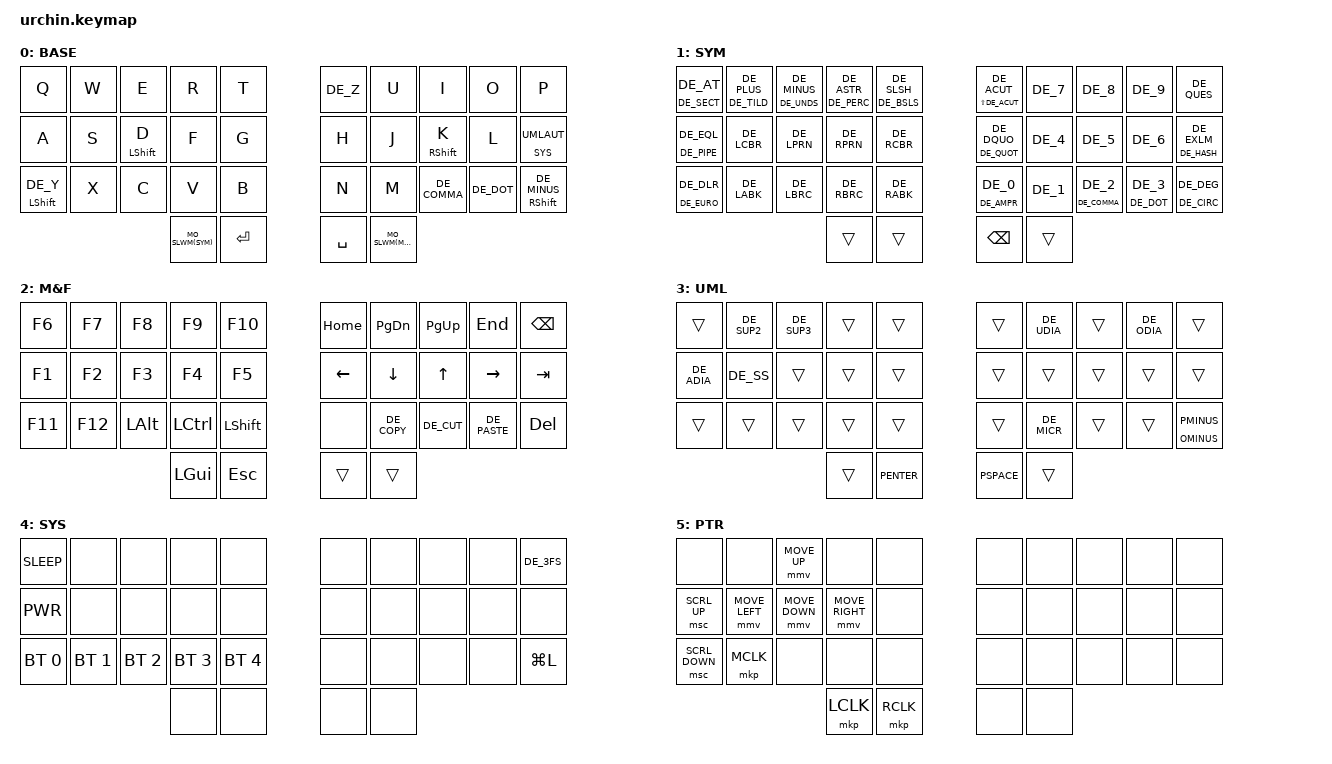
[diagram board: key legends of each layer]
/*
 * Copyright (c) 2020 The ZMK Contributors
 *
 * SPDX-License-Identifier: MIT
 */

#include <behaviors.dtsi>
#include <dt-bindings/zmk/outputs.h>
#include <dt-bindings/zmk/bt.h>
#include <dt-bindings/zmk/keys.h>

#define ZMK_POINTING_DEFAULT_MOVE_VAL 600  // default: 600
#define ZMK_POINTING_DEFAULT_SCRL_VAL 10   // default: 10
#include <dt-bindings/zmk/pointing.h>

#include "keys_de.h"

#define MO_SLWM(layer) &mo_slwm layer layer     // Momentary and sticky layer

#define DEFAULT 0
#define SYM     1
#define MOVEFKT 2
#define UMLAUT  3
#define SYS     4
#define POINTER 5

/*
 * Combos for ESC, Backspace, TAB and ENTER
 */

/ {
    combos {
        compatible = "zmk,combos";
        combo_esc {
            timeout-ms = <50>;
            key-positions = <1 2>;
            layers = <DEFAULT SYM MOVEFKT UMLAUT>;
            bindings = <&kp ESC>;
            slow-release;
        };
        combo_bksp {
            timeout-ms = <75>;
            key-positions = <7 8>;
            layers = <DEFAULT SYM MOVEFKT UMLAUT>;
            bindings = <&kp BSPC>;
            slow-release;
        };
        combo_tab {
            timeout-ms = <50>;
            key-positions = <21 22>;
            layers = <DEFAULT SYM MOVEFKT UMLAUT>;
            bindings = <&kp TAB>;
            slow-release;
        };
        combo_enter {
            timeout-ms = <50>;
            key-positions = <27 28>;
            layers = <DEFAULT SYM MOVEFKT  UMLAUT>;
            bindings = <&kp ENTER>;
            slow-release;
        };
        combo_btclr {
            timeout-ms = <50>;
            key-positions = <0 10 20>;
            layers = <SYS>;
            bindings = <&bt BT_CLR>;
        };
        combo_prefout {
            timeout-ms = <50>;
            key-positions = <4 5>;
            layers = <SYS>;
            bindings = <&out OUT_TOG>;
        };
        combo_cword {
            timeout-ms = <50>;
            key-positions = <13 16>;
            layers = <DEFAULT>;
            bindings = <&caps_word>;
        };
        combo_lctl {
            timeout-ms = <50>;
            key-positions = <12 13>;
            layers = <DEFAULT SYM MOVEFKT UMLAUT>;
            bindings = <&kp LCTL>;
            slow-release;
        };
        combo_lalt {
            timeout-ms = <50>;
            key-positions = <11 13>;
            layers = <DEFAULT SYM MOVEFKT UMLAUT>;
            bindings = <&kp LALT>;
            slow-release;
        };
        combo_lgui {
            timeout-ms = <50>;
            key-positions = <10 13>;
            layers = <DEFAULT SYM MOVEFKT UMLAUT>;
            bindings = <&kp LGUI>;
            slow-release;
        };
        combo_rctl {
            timeout-ms = <50>;
            key-positions = <16 17>;
            layers = <DEFAULT SYM MOVEFKT UMLAUT>;
            bindings = <&kp RCTL>;
            slow-release;
        };
        combo_ralt {
            timeout-ms = <50>;
            key-positions = <16 18>;
            layers = <DEFAULT SYM MOVEFKT UMLAUT>;
            bindings = <&kp LALT>;
            slow-release;
        };
        combo_rapp {
            timeout-ms = <50>;
            key-positions = <16 19>;
            layers = <DEFAULT SYM MOVEFKT UMLAUT>;
            bindings = <&kp K_APP>;
            slow-release;
        };
        combo_pointer {
            timeout-ms = <50>;
            key-positions = <17 33>;
            layers = <DEFAULT SYM MOVEFKT UMLAUT>;
            bindings = <&mo POINTER>;
            slow-release;
        };
    };
};

/ {
    macros {
        apwd: apwd {
            compatible = "zmk,behavior-macro";
            #binding-cells = <0>;
            bindings
                = <&macro_press &kp LSHFT>
                , <&macro_tap &kp S>
                , <&macro_release &kp LSHFT>
                , <&macro_tap &kp O &kp F &kp T &kp C &kp H &kp E &kp M &kp DE_MINUS &kp DE_1 &kp ENTER>
                ;
        };
    };
};

/ {

    behaviors {
      slwm: sticky_layer_with_modifiers {
        compatible = "zmk,behavior-sticky-key";
        #binding-cells = <1>;
        bindings = <&mo>;
        release-after-ms = <1000>;
        ignore-modifiers;
        #quick-release;
      };
      mo_slwm: behavior_mo_slwm {
        compatible = "zmk,behavior-hold-tap";
        #binding-cells = <2>;
        flavor = "tap-preferred";
        tapping-term-ms = <200>;
        bindings = <&mo>, <&slwm>;
        };
      hm_rt: homerow_mods_retrotap {
        compatible = "zmk,behavior-hold-tap";
        #binding-cells = <2>;
        tapping-term-ms = <200>;
        quick-tap-ms = <125>;
        flavor = "balanced";
        bindings = <&kp>, <&kp>;
        retro-tap;
      };
      hm: homerow_mods {
        compatible = "zmk,behavior-hold-tap";
        #binding-cells = <2>;
        tapping-term-ms = <200>;
        quick-tap-ms = <125>;
        flavor = "tap-preferred";
        bindings = <&kp>, <&kp>;
      };
    };


    keymap {
        compatible = "zmk,keymap";

        default_layer {
            // ---------------------------------------------------------------------------------
            // |  Q  |  W  |  E  |  R   |  T  |   |  Y  |  U   |  I  |  O  |  P  |
            // |  A  |  S  |  D  |  F   |  G  |   |  H  |  J   |  K  |  L  | SL3 |
            // |  Z  |  X  |  C  |  V   |  B  |   |  N  |  M   |  ,  |  .  |  -  |
            //                   | LALT | SPC |   | SPC | RCTL |
	    display-name = "BASE";
            bindings = <
&kp Q                &kp W            &kp E            &kp R                &kp T       &kp DE_Z          &kp U            &kp I             &kp O            &kp P              
&kp A                &kp S            &hm LSHIFT D     &kp F                &kp G       &kp H             &kp J            &hm RSHIFT K      &kp L    &mo_slwm SYS UMLAUT
&hm LSHIFT DE_Y      &kp X            &kp C            &kp V                &kp B       &kp N             &kp M            &kp DE_COMMA      &kp DE_DOT       &hm RSHIFT DE_MINUS
                                                       MO_SLWM(SYM)         &kp ENTER   &kp SPACE         MO_SLWM(MOVEFKT)   
            >;
        };

        

        symbol {
            // -----------------------------------------------------------------------------------------------------
            // | @ §    | + ~  | - _  |   * %   | / \  |   | ` ´  |  7     |  8    |  9    |   ? |
            // | = "|"  |  {   |  (   |    )    |  }   |   | " '  |  4     |  5    |  6    | ! # |
            // | $ €    |  <   |  [   |    ]    |  >   |   | 0 &  |  1     |  2 ,  |  3 .  | ° ^ |
            //                 | tran | tog SYM | tran |   | tran | K_MENU |
            display-name = "SYM";
            bindings = <
&mt DE_SECT DE_AT   &mt DE_TILD DE_PLUS  &mt DE_UNDS DE_MINUS  &mt DE_PERC DE_ASTR  &mt DE_BSLS DE_SLSH      &mt LS(DE_ACUT) DE_ACUT  &kp DE_7    &kp DE_8           &kp DE_9          &kp DE_QUES        
&mt DE_PIPE DE_EQL  &kp DE_LCBR          &kp DE_LPRN           &kp DE_RPRN          &kp DE_RCBR              &mt DE_QUOT DE_DQUO      &kp DE_4    &kp DE_5           &kp DE_6          &mt DE_HASH DE_EXLM
&mt DE_EURO DE_DLR  &kp DE_LABK          &kp DE_LBRC           &kp DE_RBRC          &kp DE_RABK              &mt DE_AMPR DE_0         &kp DE_1    &mt DE_COMMA DE_2  &mt DE_DOT DE_3   &mt DE_CIRC DE_DEG
                                                               &trans               &trans                   &kp BKSP                 &trans       
            >;
        };

        MOVEFKT  {
            // -------------------------------------------------------------------------------------------
            // | F6  | F7  | F8  | F9  | F10    |   | HOME | PG_DN  | PG_UP  | END     | BKSP |
            // | F1  | F2  | F3  | F4  | F5     |   | LEFT | DOWN   | UP     | RIGHT   | TAB  |
            // | F11 | F12 | NA  | NA  | SHIFT  |   | NA   | COPY   | CUT    | PASTE   | DEL  |
            //                   | NA  | NA     |   | NA   |  NA    |
	    display-name = "M&F";
            bindings = <
&kp F6    &kp F7  &kp F8    &kp F9        &kp F10         &kp HOME  &kp PG_DN    &kp PG_UP   &kp END       &kp BKSP  
&kp F1    &kp F2  &kp F3    &kp F4        &kp F5          &kp LEFT  &kp DOWN     &kp UP      &kp RIGHT     &kp TAB  
&kp F11   &kp F12 &kp LALT  &kp LCTL      &kp LSHIFT      &none     &kp DE_COPY  &kp DE_CUT  &kp DE_PASTE  &kp DEL  
                            &kp LGUI      &kp ESC         &trans    &trans    
            >;
        };

        umlaut {
            // -----------------------------------------------------------------------------------------
            // | tran | ²    | ²    | tran | tran |   | Ü    | tran | Ö    | tran | tran |
            // | Ä    | ß    | tran | tran | tran |   | tran | tran | tran | tran | tran |
            // | tran | tran | tran | tran | tran |   | tran | µ    | tran | tran | -    |
            //                      | tran | tran |   | tran | tran |
            display-name = "UML";
            bindings = <
&trans       &kp DE_SUP2  &kp DE_SUP3  &trans    &trans              &trans         &kp DE_UDIA  &trans  &kp DE_ODIA  &trans             
&kp DE_ADIA  &kp DE_SS    &trans       &trans    &trans              &trans         &trans       &trans  &trans       &trans             
&trans       &trans       &trans       &trans    &trans              &trans         &kp DE_MICR  &trans  &trans       &mt OMINUS PMINUS  
                                       &trans    &kp PENTER          &kp PSPACE     &trans 
            >;
        };
        
        system {
            // --------------------------------------------------------------------------------------------------------
            // | K_SLEEP  | NA       | NA       | NA       | NA       |   | NA | NA | NA | NA | DE_3FS |
            // | K_PWR    | NA       | NA       | NA       | NA       |   | NA | NA | NA | NA | NA     |
            // | BT_SEL 0 | BT_SEL 1 | BT_SEL 2 | BT_SEL 3 | BT_SEL 4 |   | NA | NA | NA | NA | K_LOCK |
            //                                  | NA       | NA       |   | NA | NA | 
            display-name = "SYS";
            bindings = <
&kp K_SLEEP   &none         &none         &none         &none             &none  &none  &none  &none  &kp DE_3FS
&kp K_PWR     &none         &none         &none         &none             &none  &none  &none  &none  &none 
&bt BT_SEL 0  &bt BT_SEL 1  &bt BT_SEL 2  &bt BT_SEL 3  &bt BT_SEL 4      &none  &none  &none  &none  &kp LG(L)
                                          &none         &none             &none  &none  
            >;
        };
        
        pointer {
            // --------------------------------------------------------------------------------------------------------
            // | NA       | NA       | NA       | NA       | NA       |   | NA | NA | NA | NA | NA |
            // | NA       | NA       | NA       | NA       | NA       |   | NA | NA | NA | NA | NA |
            // | BT_SEL 0 | BT_SEL 1 | BT_SEL 2 | BT_SEL 3 | BT_SEL 4 |   | NA | NA | NA | NA | -  |
            //                                  | NA       | NA       |   | NA | NA |
	    display-name = "PTR";
            bindings = <
&none          &none            &mmv MOVE_UP      &none             &none       &none  &none  &none  &none  &none 
&msc SCRL_UP   &mmv MOVE_LEFT   &mmv MOVE_DOWN    &mmv MOVE_RIGHT   &none       &none  &none  &none  &none  &none
&msc SCRL_DOWN &mkp MCLK        &none             &none             &none       &none  &none  &none  &none  &none
                                                  &mkp LCLK         &mkp RCLK   &none  &none  
            >;
        };

        extra1 {
            status = "reserved";
        };

        extra2 {
            status = "reserved";
        };

        extra3 {
            status = "reserved";
        };
    };
};
